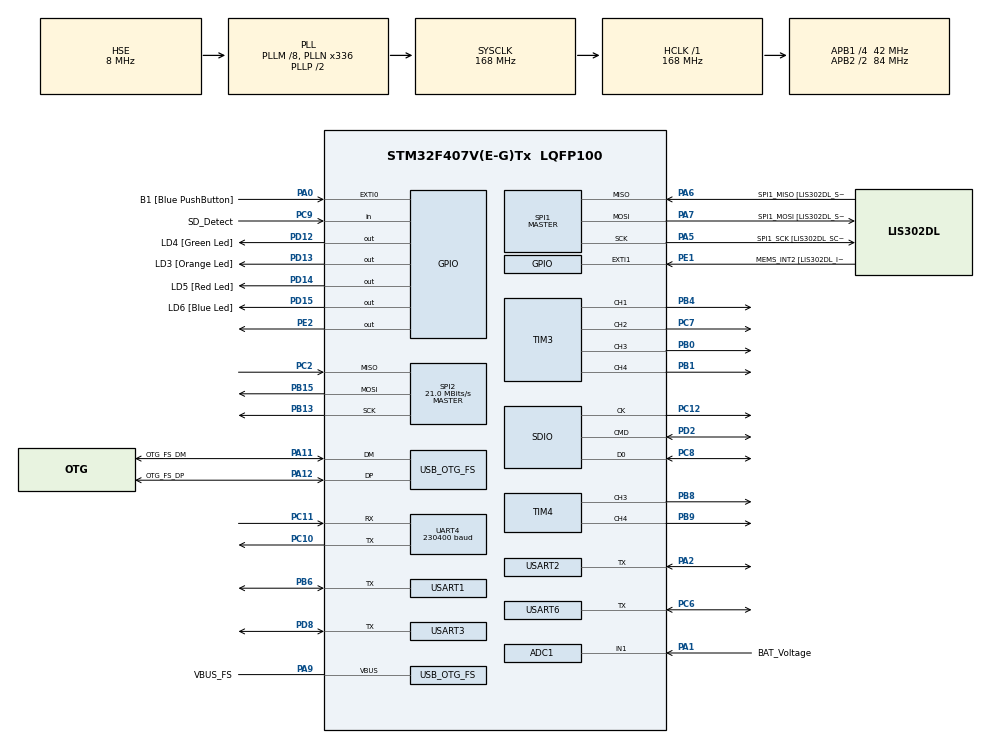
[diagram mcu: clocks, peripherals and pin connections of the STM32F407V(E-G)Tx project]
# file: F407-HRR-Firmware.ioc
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ADC1.Channel-2\#ChannelRegularConversion=ADC_CHANNEL_1
ADC1.EOCSelection=ADC_EOC_SEQ_CONV
ADC1.EnableAnalogWatchDog=false
ADC1.NbrOfConversion=1
ADC1.NbrOfConversionFlag=1
ADC1.Rank-2\#ChannelRegularConversion=1
ADC1.SamplingTime-2\#ChannelRegularConversion=ADC_SAMPLETIME_15CYCLES
ADC1.ScanConvMode=DISABLE
ADC1.master=1
Dma.ADC1.0.Direction=DMA_PERIPH_TO_MEMORY
Dma.ADC1.0.FIFOMode=DMA_FIFOMODE_DISABLE
Dma.ADC1.0.Instance=DMA2_Stream0
Dma.ADC1.0.MemDataAlignment=DMA_MDATAALIGN_WORD
Dma.ADC1.0.MemInc=DMA_MINC_ENABLE
Dma.ADC1.0.Mode=DMA_NORMAL
Dma.ADC1.0.PeriphDataAlignment=DMA_PDATAALIGN_WORD
Dma.ADC1.0.PeriphInc=DMA_PINC_DISABLE
Dma.ADC1.0.Priority=DMA_PRIORITY_LOW
Dma.Request0=ADC1
Dma.Request1=USART1_TX
Dma.Request2=USART2_TX
Dma.Request3=USART3_TX
Dma.Request4=USART6_TX
Dma.USART1_TX.1.Direction=DMA_MEMORY_TO_PERIPH
Dma.USART1_TX.1.FIFOMode=DMA_FIFOMODE_DISABLE
Dma.USART1_TX.1.Instance=DMA2_Stream7
Dma.USART1_TX.1.MemDataAlignment=DMA_MDATAALIGN_BYTE
Dma.USART1_TX.1.MemInc=DMA_MINC_ENABLE
Dma.USART1_TX.1.Mode=DMA_NORMAL
Dma.USART1_TX.1.PeriphDataAlignment=DMA_PDATAALIGN_BYTE
Dma.USART1_TX.1.PeriphInc=DMA_PINC_DISABLE
Dma.USART1_TX.1.Priority=DMA_PRIORITY_LOW
Dma.USART2_TX.2.Direction=DMA_MEMORY_TO_PERIPH
Dma.USART2_TX.2.FIFOMode=DMA_FIFOMODE_DISABLE
Dma.USART2_TX.2.Instance=DMA1_Stream6
Dma.USART2_TX.2.MemDataAlignment=DMA_MDATAALIGN_BYTE
Dma.USART2_TX.2.MemInc=DMA_MINC_ENABLE
Dma.USART2_TX.2.Mode=DMA_NORMAL
Dma.USART2_TX.2.PeriphDataAlignment=DMA_PDATAALIGN_BYTE
Dma.USART2_TX.2.PeriphInc=DMA_PINC_DISABLE
Dma.USART2_TX.2.Priority=DMA_PRIORITY_LOW
Dma.USART3_TX.3.Direction=DMA_MEMORY_TO_PERIPH
Dma.USART3_TX.3.FIFOMode=DMA_FIFOMODE_DISABLE
Dma.USART3_TX.3.Instance=DMA1_Stream3
Dma.USART3_TX.3.MemDataAlignment=DMA_MDATAALIGN_BYTE
Dma.USART3_TX.3.MemInc=DMA_MINC_ENABLE
Dma.USART3_TX.3.Mode=DMA_NORMAL
Dma.USART3_TX.3.PeriphDataAlignment=DMA_PDATAALIGN_BYTE
Dma.USART3_TX.3.PeriphInc=DMA_PINC_DISABLE
Dma.USART3_TX.3.Priority=DMA_PRIORITY_LOW
Dma.USART6_TX.4.Direction=DMA_MEMORY_TO_PERIPH
Dma.USART6_TX.4.FIFOMode=DMA_FIFOMODE_DISABLE
Dma.USART6_TX.4.Instance=DMA2_Stream6
Dma.USART6_TX.4.MemDataAlignment=DMA_MDATAALIGN_BYTE
Dma.USART6_TX.4.MemInc=DMA_MINC_ENABLE
Dma.USART6_TX.4.Mode=DMA_NORMAL
Dma.USART6_TX.4.PeriphDataAlignment=DMA_PDATAALIGN_BYTE
Dma.USART6_TX.4.PeriphInc=DMA_PINC_DISABLE
Dma.USART6_TX.4.Priority=DMA_PRIORITY_LOW
FATFS.BSP.number=1
FATFS._FS_LOCK=16
FATFS0.BSP.STBoard=false
FATFS0.BSP.api=Unknown
FATFS0.BSP.instance=PC9
FATFS0.BSP.ip=GPIO
FATFS0.BSP.mode=Input
FATFS0.BSP.name=Detect_SDIO
FATFS0.BSP.solution=PC9
Mcu.Family=STM32F4
Mcu.Name=STM32F407V(E-G)Tx
Mcu.Package=LQFP100
NVIC.DMA1_Stream3_IRQn=true\:0\:0\:false\:false\:true\:false\:true\:true
NVIC.DMA1_Stream6_IRQn=true\:0\:0\:false\:false\:true\:false\:true\:true
NVIC.DMA2_Stream0_IRQn=true\:0\:0\:false\:false\:true\:false\:true\:true
NVIC.DMA2_Stream6_IRQn=true\:0\:0\:false\:false\:true\:false\:true\:true
NVIC.DMA2_Stream7_IRQn=true\:0\:0\:false\:false\:true\:false\:true\:true
NVIC.OTG_FS_IRQn=true\:0\:0\:false\:false\:true\:true\:true\:true
NVIC.PriorityGroup=NVIC_PRIORITYGROUP_4
NVIC.TIM6_DAC_IRQn=true\:8\:0\:true\:false\:true\:true\:true\:true
NVIC.UART4_IRQn=true\:0\:0\:false\:false\:true\:true\:true\:true
NVIC.USART1_IRQn=true\:0\:0\:false\:false\:true\:true\:true\:true
NVIC.USART2_IRQn=true\:0\:0\:false\:false\:true\:true\:true\:true
NVIC.USART3_IRQn=true\:0\:0\:false\:false\:true\:true\:true\:true
NVIC.USART6_IRQn=true\:0\:0\:false\:false\:true\:true\:true\:true
PA0-WKUP.GPIO_Label=B1 [Blue PushButton]
PA0-WKUP.GPIO_ModeDefaultEXTI=GPIO_MODE_EVT_RISING
PA0-WKUP.GPIO_PuPd=GPIO_NOPULL
PA0-WKUP.Signal=GPXTI0
PA1.GPIO_Label=BAT_Voltage
PA1.Signal=SharedAnalog_PA1
PA10.GPIO_Label=OTG_FS_ID
PA10.GPIO_Mode=GPIO_MODE_AF_PP
PA10.GPIO_PuPd=GPIO_NOPULL
PA10.GPIO_Speed=GPIO_SPEED_FREQ_LOW
PA10.Signal=USB_OTG_FS_ID
PA11.GPIO_Label=OTG_FS_DM
PA11.GPIO_Mode=GPIO_MODE_AF_PP
PA11.GPIO_PuPd=GPIO_NOPULL
PA11.GPIO_Speed=GPIO_SPEED_FREQ_LOW
PA11.Mode=Device_Only
PA11.Signal=USB_OTG_FS_DM
PA12.GPIO_Label=OTG_FS_DP
PA12.GPIO_Mode=GPIO_MODE_AF_PP
PA12.GPIO_PuPd=GPIO_NOPULL
PA12.GPIO_Speed=GPIO_SPEED_FREQ_LOW
PA12.Mode=Device_Only
PA12.Signal=USB_OTG_FS_DP
PA13.GPIO_Label=SWDIO
PA13.Mode=Serial_Wire
PA13.Signal=SYS_JTMS-SWDIO
PA14.GPIO_Label=SWCLK
PA14.Mode=Serial_Wire
PA14.Signal=SYS_JTCK-SWCLK
PA2.GPIO_ModeDefaultOD=GPIO_MODE_AF_PP
PA2.GPIO_PuPd=GPIO_PULLUP
PA2.Mode=Half_duplex(single_wire_mode)
PA2.Signal=USART2_TX
PA5.GPIO_Label=SPI1_SCK [LIS302DL_SCL/SPC]
PA5.GPIO_Mode=GPIO_MODE_AF_PP
PA5.GPIO_PuPd=GPIO_NOPULL
PA5.GPIO_Speed=GPIO_SPEED_FREQ_LOW
PA5.Mode=Full_Duplex_Master
PA5.Signal=SPI1_SCK
PA6.GPIO_Label=SPI1_MISO [LIS302DL_SDO]
PA6.GPIO_Mode=GPIO_MODE_AF_PP
PA6.GPIO_PuPd=GPIO_NOPULL
PA6.GPIO_Speed=GPIO_SPEED_FREQ_LOW
PA6.Mode=Full_Duplex_Master
PA6.Signal=SPI1_MISO
PA7.GPIO_Label=SPI1_MOSI [LIS302DL_SDA/SDI/SDO]
PA7.GPIO_Mode=GPIO_MODE_AF_PP
PA7.GPIO_PuPd=GPIO_NOPULL
PA7.GPIO_Speed=GPIO_SPEED_FREQ_LOW
PA7.Mode=Full_Duplex_Master
PA7.Signal=SPI1_MOSI
PA9.GPIO_Label=VBUS_FS
PA9.GPIO_Mode=GPIO_MODE_INPUT
PA9.GPIO_PuPd=GPIO_NOPULL
PA9.Mode=Activate_VBUS
PA9.Signal=USB_OTG_FS_VBUS
PB0.Signal=S_TIM3_CH3
PB1.Signal=S_TIM3_CH4
PB10.GPIO_Label=CLK_IN [MP45DT02_CLK]
PB10.GPIO_Mode=GPIO_MODE_AF_PP
PB10.GPIO_PuPd=GPIO_NOPULL
PB10.GPIO_Speed=GPIO_SPEED_FREQ_LOW
PB10.Signal=I2S2_CK
PB13.Mode=Full_Duplex_Master
PB13.Signal=SPI2_SCK
PB15.Mode=Full_Duplex_Master
PB15.Signal=SPI2_MOSI
PB3.GPIO_Label=SWO
PB3.Signal=SYS_JTDO-SWO
PB4.Signal=S_TIM3_CH1
PB6.GPIO_ModeDefaultOD=GPIO_MODE_AF_PP
PB6.GPIO_PuPd=GPIO_PULLUP
PB6.Mode=Half_duplex(single_wire_mode)
PB6.Signal=USART1_TX
PB8.Signal=S_TIM4_CH3
PB9.Signal=S_TIM4_CH4
PC10.Mode=Asynchronous
PC10.Signal=UART4_TX
PC11.GPIO_PuPd=GPIO_PULLUP
PC11.Mode=Asynchronous
PC11.Signal=UART4_RX
PC12.Mode=SD_1_bit
PC12.Signal=SDIO_CK
PC14-OSC32_IN.GPIO_Label=PC14-OSC32_IN
PC14-OSC32_IN.Mode=LSE-External-Oscillator
PC14-OSC32_IN.Signal=RCC_OSC32_IN
PC15-OSC32_OUT.GPIO_Label=PC15-OSC32_OUT
PC15-OSC32_OUT.Mode=LSE-External-Oscillator
PC15-OSC32_OUT.Signal=RCC_OSC32_OUT
PC2.Mode=Full_Duplex_Master
PC2.Signal=SPI2_MISO
PC3.GPIO_Label=PDM_OUT [MP45DT02_DOUT]
PC3.GPIO_Mode=GPIO_MODE_AF_PP
PC3.GPIO_PuPd=GPIO_NOPULL
PC3.GPIO_Speed=GPIO_SPEED_FREQ_LOW
PC3.Signal=I2S2_SD
PC6.GPIO_ModeDefaultOD=GPIO_MODE_AF_PP
PC6.GPIO_PuPd=GPIO_PULLUP
PC6.Mode=Half_duplex(single_wire_mode)
PC6.Signal=USART6_TX
PC7.Signal=S_TIM3_CH2
PC8.Mode=SD_1_bit
PC8.Signal=SDIO_D0
PC9.GPIO_Label=SD_Detect
PC9.GPIO_PuPd=GPIO_PULLDOWN
PC9.Signal=GPIO_Input
PD12.GPIO_Label=LD4 [Green Led]
PD12.GPIO_PuPd=GPIO_NOPULL
PD12.GPIO_Speed=GPIO_SPEED_FREQ_LOW
PD12.Signal=GPIO_Output
PD13.GPIO_Label=LD3 [Orange Led]
PD13.Signal=GPIO_Output
PD14.GPIO_Label=LD5 [Red Led]
PD14.GPIO_PuPd=GPIO_NOPULL
PD14.GPIO_Speed=GPIO_SPEED_FREQ_LOW
PD14.Signal=GPIO_Output
PD15.GPIO_Label=LD6 [Blue Led]
PD15.GPIO_PuPd=GPIO_NOPULL
PD15.GPIO_Speed=GPIO_SPEED_FREQ_LOW
PD15.Signal=GPIO_Output
PD2.Mode=SD_1_bit
PD2.Signal=SDIO_CMD
PD8.GPIO_ModeDefaultOD=GPIO_MODE_AF_PP
PD8.GPIO_PuPd=GPIO_PULLUP
PD8.Mode=Half_duplex(single_wire_mode)
PD8.Signal=USART3_TX
PE1.GPIO_Label=MEMS_INT2 [LIS302DL_INT2]
PE1.GPIO_ModeDefaultEXTI=GPIO_MODE_EVT_RISING
PE1.GPIO_PuPd=GPIO_NOPULL
PE1.Signal=GPXTI1
PE2.Signal=GPIO_Output
PH0-OSC_IN.GPIO_Label=PH0-OSC_IN
PH0-OSC_IN.Mode=HSE-External-Oscillator
PH0-OSC_IN.Signal=RCC_OSC_IN
PH1-OSC_OUT.GPIO_Label=PH1-OSC_OUT
PH1-OSC_OUT.Mode=HSE-External-Oscillator
PH1-OSC_OUT.Signal=RCC_OSC_OUT
ProjectManager.HeapSize=0x200
ProjectManager.StackSize=0x400
ProjectManager.TargetToolchain=STM32CubeIDE
RCC.48MHZClocksFreq_Value=48000000
RCC.AHBFreq_Value=168000000
RCC.APB1CLKDivider=RCC_HCLK_DIV4
RCC.APB1Freq_Value=42000000
RCC.APB1TimFreq_Value=84000000
RCC.APB2CLKDivider=RCC_HCLK_DIV2
RCC.APB2Freq_Value=84000000
RCC.APB2TimFreq_Value=168000000
RCC.CortexFreq_Value=168000000
RCC.HCLKFreq_Value=168000000
RCC.HSE_VALUE=8000000
RCC.HSI_VALUE=16000000
RCC.PLLM=8
RCC.PLLN=336
RCC.PLLQ=7
RCC.SYSCLKFreq_VALUE=168000000
RCC.SYSCLKSource=RCC_SYSCLKSOURCE_PLLCLK
RCC.VCOOutputFreq_Value=336000000
SH.S_TIM3_CH1.0=TIM3_CH1,PWM Generation1 CH1
SH.S_TIM3_CH2.0=TIM3_CH2,PWM Generation2 CH2
SH.S_TIM3_CH3.0=TIM3_CH3,PWM Generation3 CH3
SH.S_TIM3_CH4.0=TIM3_CH4,PWM Generation4 CH4
SH.S_TIM4_CH3.0=TIM4_CH3,PWM Generation3 CH3
SH.S_TIM4_CH4.0=TIM4_CH4,PWM Generation4 CH4
SH.SharedAnalog_PA1.0=GPIO_Analog
SH.SharedAnalog_PA1.1=ADC1_IN1,IN1
SPI1.BaudRatePrescaler-Full_Duplex_Master=SPI_BAUDRATEPRESCALER_2
SPI1.CalculateBaudRate-Full_Duplex_Master=42.0 MBits/s
SPI1.Direction=SPI_DIRECTION_2LINES
SPI1.Mode=SPI_MODE_MASTER
SPI1.Mode-Full_Duplex_Master=SPI_MODE_MASTER
SPI1.VirtualType=VM_MASTER
SPI2.CalculateBaudRate=21.0 MBits/s
SPI2.Direction=SPI_DIRECTION_2LINES
SPI2.Mode=SPI_MODE_MASTER
SPI2.VirtualType=VM_MASTER
TIM3.Channel-PWM\ Generation1\ CH1=TIM_CHANNEL_1
TIM3.Channel-PWM\ Generation2\ CH2=TIM_CHANNEL_2
TIM3.Channel-PWM\ Generation3\ CH3=TIM_CHANNEL_3
TIM3.Channel-PWM\ Generation4\ CH4=TIM_CHANNEL_4
TIM4.Channel-PWM\ Generation3\ CH3=TIM_CHANNEL_3
TIM4.Channel-PWM\ Generation4\ CH4=TIM_CHANNEL_4
TIM6.Period=99
TIM6.Prescaler=8399
UART4.BaudRate=230400
UART4.VirtualMode=Asynchronous
USART1.BaudRate=1000000
USART1.VirtualMode=VM_ASYNC
USART2.BaudRate=1000000
USART2.VirtualMode=VM_ASYNC
USART3.BaudRate=1000000
USART3.VirtualMode=VM_ASYNC
USART6.BaudRate=1000000
USART6.VirtualMode=VM_ASYNC
USB_DEVICE.CLASS_NAME_FS=CDC
USB_DEVICE.VirtualMode-CDC_FS=Cdc
USB_DEVICE.VirtualModeFS=Cdc_FS
USB_OTG_FS.VirtualMode=Device_Only
VP_ADC1_TempSens_Input.Mode=IN-TempSens
VP_ADC1_Vref_Input.Mode=IN-Vrefint
VP_FATFS_VS_SDIO.Mode=SDIO
VP_TIM6_VS_ClockSourceINT.Mode=Enable_Timer
VP_USB_DEVICE_VS_USB_DEVICE_CDC_FS.Mode=CDC_FS
board=STM32F407G-DISC1

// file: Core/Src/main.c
/* USER CODE BEGIN Header */
/**
  ******************************************************************************
  * @file           : main.c
  * @brief          : Main program body
  ******************************************************************************
  * @attention
  *
  * Copyright (c) 2022 STMicroelectronics.
  * All rights reserved.
  *
  * This software is licensed under terms that can be found in the LICENSE file
  * in the root directory of this software component.
  * If no LICENSE file comes with this software, it is provided AS-IS.
  *
  ******************************************************************************
  */
/* USER CODE END Header */
#include "main.h"
#include "fatfs.h"
#include "usb_device.h"

/* USER CODE BEGIN Includes */
#include "Components\Start.hpp"
/* USER CODE END Includes */

 ADC_HandleTypeDef hadc1;
DMA_HandleTypeDef hdma_adc1;

SD_HandleTypeDef hsd;

SPI_HandleTypeDef hspi1;
SPI_HandleTypeDef hspi2;

TIM_HandleTypeDef htim3;
TIM_HandleTypeDef htim4;
TIM_HandleTypeDef htim6;

UART_HandleTypeDef huart4;
UART_HandleTypeDef huart1;
UART_HandleTypeDef huart2;
UART_HandleTypeDef huart3;
UART_HandleTypeDef huart6;
DMA_HandleTypeDef hdma_usart1_tx;
DMA_HandleTypeDef hdma_usart2_tx;
DMA_HandleTypeDef hdma_usart3_tx;
DMA_HandleTypeDef hdma_usart6_tx;

void SystemClock_Config(void);
static void MX_GPIO_Init(void);
static void MX_SPI1_Init(void);
static void MX_SDIO_SD_Init(void);
static void MX_DMA_Init(void);
static void MX_SPI2_Init(void);
static void MX_TIM3_Init(void);
static void MX_TIM4_Init(void);
static void MX_TIM6_Init(void);
static void MX_USART1_UART_Init(void);
static void MX_USART2_UART_Init(void);
static void MX_USART3_UART_Init(void);
static void MX_USART6_UART_Init(void);
static void MX_ADC1_Init(void);
static void MX_UART4_Init(void);

int main(void)
{

  /* MCU Configuration--------------------------------------------------------*/

  /* Reset of all peripherals, Initializes the Flash interface and the Systick. */
  HAL_Init();

  /* Configure the system clock */
  SystemClock_Config();

  /* Initialize all configured peripherals */
  MX_GPIO_Init();
  MX_SPI1_Init();
  MX_USB_DEVICE_Init();
  MX_SDIO_SD_Init();
  MX_FATFS_Init();
  MX_DMA_Init();
  MX_SPI2_Init();
  MX_TIM3_Init();
  MX_TIM4_Init();
  MX_TIM6_Init();
  MX_USART1_UART_Init();
  MX_USART2_UART_Init();
  MX_USART3_UART_Init();
  MX_USART6_UART_Init();
  MX_ADC1_Init();
  MX_UART4_Init();
  /* USER CODE BEGIN 2 */
  HAL_TIM_Base_Start_IT(&htim6);
  Start();
  /* USER CODE END 2 */

  /* Infinite loop */
  /* USER CODE BEGIN WHILE */
  //Não deve chegar aqui
  while (1)
  {
    /* USER CODE END WHILE */

  }
}

void SystemClock_Config(void)
{
  RCC_OscInitTypeDef RCC_OscInitStruct = {0};
  RCC_ClkInitTypeDef RCC_ClkInitStruct = {0};

  /** Configure the main internal regulator output voltage
  */
  __HAL_RCC_PWR_CLK_ENABLE();
  __HAL_PWR_VOLTAGESCALING_CONFIG(PWR_REGULATOR_VOLTAGE_SCALE1);

  /** Initializes the RCC Oscillators according to the specified parameters
  * in the RCC_OscInitTypeDef structure.
  */
  RCC_OscInitStruct.OscillatorType = RCC_OSCILLATORTYPE_HSE;
  RCC_OscInitStruct.HSEState = RCC_HSE_ON;
  RCC_OscInitStruct.PLL.PLLState = RCC_PLL_ON;
  RCC_OscInitStruct.PLL.PLLSource = RCC_PLLSOURCE_HSE;
  RCC_OscInitStruct.PLL.PLLM = 8;
  RCC_OscInitStruct.PLL.PLLN = 336;
  RCC_OscInitStruct.PLL.PLLP = RCC_PLLP_DIV2;
  RCC_OscInitStruct.PLL.PLLQ = 7;
  if (HAL_RCC_OscConfig(&RCC_OscInitStruct) != HAL_OK)
  {
    Error_Handler();
  }

  /** Initializes the CPU, AHB and APB buses clocks
  */
  RCC_ClkInitStruct.ClockType = RCC_CLOCKTYPE_HCLK|RCC_CLOCKTYPE_SYSCLK
                              |RCC_CLOCKTYPE_PCLK1|RCC_CLOCKTYPE_PCLK2;
  RCC_ClkInitStruct.SYSCLKSource = RCC_SYSCLKSOURCE_PLLCLK;
  RCC_ClkInitStruct.AHBCLKDivider = RCC_SYSCLK_DIV1;
  RCC_ClkInitStruct.APB1CLKDivider = RCC_HCLK_DIV4;
  RCC_ClkInitStruct.APB2CLKDivider = RCC_HCLK_DIV2;

  if (HAL_RCC_ClockConfig(&RCC_ClkInitStruct, FLASH_LATENCY_5) != HAL_OK)
  {
    Error_Handler();
  }
}

static void MX_ADC1_Init(void)
{

  ADC_ChannelConfTypeDef sConfig = {0};

  /** Configure the global features of the ADC (Clock, Resolution, Data Alignment and number of conversion)
  */
  hadc1.Instance = ADC1;
  hadc1.Init.ClockPrescaler = ADC_CLOCK_SYNC_PCLK_DIV4;
  hadc1.Init.Resolution = ADC_RESOLUTION_12B;
  hadc1.Init.ScanConvMode = DISABLE;
  hadc1.Init.ContinuousConvMode = DISABLE;
  hadc1.Init.DiscontinuousConvMode = DISABLE;
  hadc1.Init.ExternalTrigConvEdge = ADC_EXTERNALTRIGCONVEDGE_NONE;
  hadc1.Init.ExternalTrigConv = ADC_SOFTWARE_START;
  hadc1.Init.DataAlign = ADC_DATAALIGN_RIGHT;
  hadc1.Init.NbrOfConversion = 1;
  hadc1.Init.DMAContinuousRequests = DISABLE;
  hadc1.Init.EOCSelection = ADC_EOC_SEQ_CONV;
  if (HAL_ADC_Init(&hadc1) != HAL_OK)
  {
    Error_Handler();
  }

  /** Configure for the selected ADC regular channel its corresponding rank in the sequencer and its sample time.
  */
  sConfig.Channel = ADC_CHANNEL_1;
  sConfig.Rank = 1;
  sConfig.SamplingTime = ADC_SAMPLETIME_15CYCLES;
  if (HAL_ADC_ConfigChannel(&hadc1, &sConfig) != HAL_OK)
  {
    Error_Handler();
  }

}

static void MX_SDIO_SD_Init(void)
{

  hsd.Instance = SDIO;
  hsd.Init.ClockEdge = SDIO_CLOCK_EDGE_RISING;
  hsd.Init.ClockBypass = SDIO_CLOCK_BYPASS_DISABLE;
  hsd.Init.ClockPowerSave = SDIO_CLOCK_POWER_SAVE_DISABLE;
  hsd.Init.BusWide = SDIO_BUS_WIDE_1B;
  hsd.Init.HardwareFlowControl = SDIO_HARDWARE_FLOW_CONTROL_DISABLE;
  hsd.Init.ClockDiv = 0;

}

static void MX_SPI1_Init(void)
{

  /* SPI1 parameter configuration*/
  hspi1.Instance = SPI1;
  hspi1.Init.Mode = SPI_MODE_MASTER;
  hspi1.Init.Direction = SPI_DIRECTION_2LINES;
  hspi1.Init.DataSize = SPI_DATASIZE_8BIT;
  hspi1.Init.CLKPolarity = SPI_POLARITY_LOW;
  hspi1.Init.CLKPhase = SPI_PHASE_1EDGE;
  hspi1.Init.NSS = SPI_NSS_SOFT;
  hspi1.Init.BaudRatePrescaler = SPI_BAUDRATEPRESCALER_2;
  hspi1.Init.FirstBit = SPI_FIRSTBIT_MSB;
  hspi1.Init.TIMode = SPI_TIMODE_DISABLE;
  hspi1.Init.CRCCalculation = SPI_CRCCALCULATION_DISABLE;
  hspi1.Init.CRCPolynomial = 10;
  if (HAL_SPI_Init(&hspi1) != HAL_OK)
  {
    Error_Handler();
  }

}

static void MX_SPI2_Init(void)
{

  /* SPI2 parameter configuration*/
  hspi2.Instance = SPI2;
  hspi2.Init.Mode = SPI_MODE_MASTER;
  hspi2.Init.Direction = SPI_DIRECTION_2LINES;
  hspi2.Init.DataSize = SPI_DATASIZE_8BIT;
  hspi2.Init.CLKPolarity = SPI_POLARITY_LOW;
  hspi2.Init.CLKPhase = SPI_PHASE_1EDGE;
  hspi2.Init.NSS = SPI_NSS_SOFT;
  hspi2.Init.BaudRatePrescaler = SPI_BAUDRATEPRESCALER_2;
  hspi2.Init.FirstBit = SPI_FIRSTBIT_MSB;
  hspi2.Init.TIMode = SPI_TIMODE_DISABLE;
  hspi2.Init.CRCCalculation = SPI_CRCCALCULATION_DISABLE;
  hspi2.Init.CRCPolynomial = 10;
  if (HAL_SPI_Init(&hspi2) != HAL_OK)
  {
    Error_Handler();
  }

}

static void MX_TIM3_Init(void)
{

  TIM_MasterConfigTypeDef sMasterConfig = {0};
  TIM_OC_InitTypeDef sConfigOC = {0};

  htim3.Instance = TIM3;
  htim3.Init.Prescaler = 0;
  htim3.Init.CounterMode = TIM_COUNTERMODE_UP;
  htim3.Init.Period = 65535;
  htim3.Init.ClockDivision = TIM_CLOCKDIVISION_DIV1;
  htim3.Init.AutoReloadPreload = TIM_AUTORELOAD_PRELOAD_DISABLE;
  if (HAL_TIM_PWM_Init(&htim3) != HAL_OK)
  {
    Error_Handler();
  }
  sMasterConfig.MasterOutputTrigger = TIM_TRGO_RESET;
  sMasterConfig.MasterSlaveMode = TIM_MASTERSLAVEMODE_DISABLE;
  if (HAL_TIMEx_MasterConfigSynchronization(&htim3, &sMasterConfig) != HAL_OK)
  {
    Error_Handler();
  }
  sConfigOC.OCMode = TIM_OCMODE_PWM1;
  sConfigOC.Pulse = 0;
  sConfigOC.OCPolarity = TIM_OCPOLARITY_HIGH;
  sConfigOC.OCFastMode = TIM_OCFAST_DISABLE;
  if (HAL_TIM_PWM_ConfigChannel(&htim3, &sConfigOC, TIM_CHANNEL_1) != HAL_OK)
  {
    Error_Handler();
  }
  if (HAL_TIM_PWM_ConfigChannel(&htim3, &sConfigOC, TIM_CHANNEL_2) != HAL_OK)
  {
    Error_Handler();
  }
  if (HAL_TIM_PWM_ConfigChannel(&htim3, &sConfigOC, TIM_CHANNEL_3) != HAL_OK)
  {
    Error_Handler();
  }
  if (HAL_TIM_PWM_ConfigChannel(&htim3, &sConfigOC, TIM_CHANNEL_4) != HAL_OK)
  {
    Error_Handler();
  }
  HAL_TIM_MspPostInit(&htim3);

}

static void MX_TIM4_Init(void)
{

  TIM_MasterConfigTypeDef sMasterConfig = {0};
  TIM_OC_InitTypeDef sConfigOC = {0};

  htim4.Instance = TIM4;
  htim4.Init.Prescaler = 0;
  htim4.Init.CounterMode = TIM_COUNTERMODE_UP;
  htim4.Init.Period = 65535;
  htim4.Init.ClockDivision = TIM_CLOCKDIVISION_DIV1;
  htim4.Init.AutoReloadPreload = TIM_AUTORELOAD_PRELOAD_DISABLE;
  if (HAL_TIM_PWM_Init(&htim4) != HAL_OK)
  {
    Error_Handler();
  }
  sMasterConfig.MasterOutputTrigger = TIM_TRGO_RESET;
  sMasterConfig.MasterSlaveMode = TIM_MASTERSLAVEMODE_DISABLE;
  if (HAL_TIMEx_MasterConfigSynchronization(&htim4, &sMasterConfig) != HAL_OK)
  {
    Error_Handler();
  }
  sConfigOC.OCMode = TIM_OCMODE_PWM1;
  sConfigOC.Pulse = 0;
  sConfigOC.OCPolarity = TIM_OCPOLARITY_HIGH;
  sConfigOC.OCFastMode = TIM_OCFAST_DISABLE;
  if (HAL_TIM_PWM_ConfigChannel(&htim4, &sConfigOC, TIM_CHANNEL_3) != HAL_OK)
  {
    Error_Handler();
  }
  if (HAL_TIM_PWM_ConfigChannel(&htim4, &sConfigOC, TIM_CHANNEL_4) != HAL_OK)
  {
    Error_Handler();
  }
  HAL_TIM_MspPostInit(&htim4);

}

static void MX_TIM6_Init(void)
{

  TIM_MasterConfigTypeDef sMasterConfig = {0};

  htim6.Instance = TIM6;
  htim6.Init.Prescaler = 8399;
  htim6.Init.CounterMode = TIM_COUNTERMODE_UP;
  htim6.Init.Period = 99;
  htim6.Init.AutoReloadPreload = TIM_AUTORELOAD_PRELOAD_DISABLE;
  if (HAL_TIM_Base_Init(&htim6) != HAL_OK)
  {
    Error_Handler();
  }
  sMasterConfig.MasterOutputTrigger = TIM_TRGO_RESET;
  sMasterConfig.MasterSlaveMode = TIM_MASTERSLAVEMODE_DISABLE;
  if (HAL_TIMEx_MasterConfigSynchronization(&htim6, &sMasterConfig) != HAL_OK)
  {
    Error_Handler();
  }

}

static void MX_UART4_Init(void)
{

  huart4.Instance = UART4;
  huart4.Init.BaudRate = 230400;
  huart4.Init.WordLength = UART_WORDLENGTH_8B;
  huart4.Init.StopBits = UART_STOPBITS_1;
  huart4.Init.Parity = UART_PARITY_NONE;
  huart4.Init.Mode = UART_MODE_TX_RX;
  huart4.Init.HwFlowCtl = UART_HWCONTROL_NONE;
  huart4.Init.OverSampling = UART_OVERSAMPLING_16;
  if (HAL_UART_Init(&huart4) != HAL_OK)
  {
    Error_Handler();
  }

}

static void MX_USART1_UART_Init(void)
{

  huart1.Instance = USART1;
  huart1.Init.BaudRate = 1000000;
  huart1.Init.WordLength = UART_WORDLENGTH_8B;
  huart1.Init.StopBits = UART_STOPBITS_1;
  huart1.Init.Parity = UART_PARITY_NONE;
  huart1.Init.Mode = UART_MODE_TX_RX;
  huart1.Init.HwFlowCtl = UART_HWCONTROL_NONE;
  huart1.Init.OverSampling = UART_OVERSAMPLING_16;
  if (HAL_HalfDuplex_Init(&huart1) != HAL_OK)
  {
    Error_Handler();
  }

}

static void MX_USART2_UART_Init(void)
{

  huart2.Instance = USART2;
  huart2.Init.BaudRate = 1000000;
  huart2.Init.WordLength = UART_WORDLENGTH_8B;
  huart2.Init.StopBits = UART_STOPBITS_1;
  huart2.Init.Parity = UART_PARITY_NONE;
  huart2.Init.Mode = UART_MODE_TX_RX;
  huart2.Init.HwFlowCtl = UART_HWCONTROL_NONE;
  huart2.Init.OverSampling = UART_OVERSAMPLING_16;
  if (HAL_HalfDuplex_Init(&huart2) != HAL_OK)
  {
    Error_Handler();
  }

}

static void MX_USART3_UART_Init(void)
{

  huart3.Instance = USART3;
  huart3.Init.BaudRate = 1000000;
  huart3.Init.WordLength = UART_WORDLENGTH_8B;
  huart3.Init.StopBits = UART_STOPBITS_1;
  huart3.Init.Parity = UART_PARITY_NONE;
  huart3.Init.Mode = UART_MODE_TX_RX;
  huart3.Init.HwFlowCtl = UART_HWCONTROL_NONE;
  huart3.Init.OverSampling = UART_OVERSAMPLING_16;
  if (HAL_HalfDuplex_Init(&huart3) != HAL_OK)
  {
    Error_Handler();
  }

}

static void MX_USART6_UART_Init(void)
{

  huart6.Instance = USART6;
  huart6.Init.BaudRate = 1000000;
  huart6.Init.WordLength = UART_WORDLENGTH_8B;
  huart6.Init.StopBits = UART_STOPBITS_1;
  huart6.Init.Parity = UART_PARITY_NONE;
  huart6.Init.Mode = UART_MODE_TX_RX;
  huart6.Init.HwFlowCtl = UART_HWCONTROL_NONE;
  huart6.Init.OverSampling = UART_OVERSAMPLING_16;
  if (HAL_HalfDuplex_Init(&huart6) != HAL_OK)
  {
    Error_Handler();
  }

}

static void MX_DMA_Init(void)
{

  /* DMA controller clock enable */
  __HAL_RCC_DMA2_CLK_ENABLE();
  __HAL_RCC_DMA1_CLK_ENABLE();

  /* DMA interrupt init */
  /* DMA1_Stream3_IRQn interrupt configuration */
  HAL_NVIC_SetPriority(DMA1_Stream3_IRQn, 0, 0);
  HAL_NVIC_EnableIRQ(DMA1_Stream3_IRQn);
  /* DMA1_Stream6_IRQn interrupt configuration */
  HAL_NVIC_SetPriority(DMA1_Stream6_IRQn, 0, 0);
  HAL_NVIC_EnableIRQ(DMA1_Stream6_IRQn);
  /* DMA2_Stream0_IRQn interrupt configuration */
  HAL_NVIC_SetPriority(DMA2_Stream0_IRQn, 0, 0);
  HAL_NVIC_EnableIRQ(DMA2_Stream0_IRQn);
  /* DMA2_Stream6_IRQn interrupt configuration */
  HAL_NVIC_SetPriority(DMA2_Stream6_IRQn, 0, 0);
  HAL_NVIC_EnableIRQ(DMA2_Stream6_IRQn);
  /* DMA2_Stream7_IRQn interrupt configuration */
  HAL_NVIC_SetPriority(DMA2_Stream7_IRQn, 0, 0);
  HAL_NVIC_EnableIRQ(DMA2_Stream7_IRQn);

}

static void MX_GPIO_Init(void)
{
  GPIO_InitTypeDef GPIO_InitStruct = {0};

  /* GPIO Ports Clock Enable */
  __HAL_RCC_GPIOE_CLK_ENABLE();
  __HAL_RCC_GPIOC_CLK_ENABLE();
  __HAL_RCC_GPIOH_CLK_ENABLE();
  __HAL_RCC_GPIOA_CLK_ENABLE();
  __HAL_RCC_GPIOB_CLK_ENABLE();
  __HAL_RCC_GPIOD_CLK_ENABLE();

  /*Configure GPIO pin Output Level */
  HAL_GPIO_WritePin(GPIOE, GPIO_PIN_2, GPIO_PIN_RESET);

  /*Configure GPIO pin Output Level */
  HAL_GPIO_WritePin(GPIOD, LD4_Pin|LD3_Pin|LD5_Pin|LD6_Pin, GPIO_PIN_RESET);

  /*Configure GPIO pin : PE2 */
  GPIO_InitStruct.Pin = GPIO_PIN_2;
  GPIO_InitStruct.Mode = GPIO_MODE_OUTPUT_PP;
  GPIO_InitStruct.Pull = GPIO_NOPULL;
  GPIO_InitStruct.Speed = GPIO_SPEED_FREQ_LOW;
  HAL_GPIO_Init(GPIOE, &GPIO_InitStruct);

  /*Configure GPIO pin : PDM_OUT_Pin */
  GPIO_InitStruct.Pin = PDM_OUT_Pin;
  GPIO_InitStruct.Mode = GPIO_MODE_AF_PP;
  GPIO_InitStruct.Pull = GPIO_NOPULL;
  GPIO_InitStruct.Speed = GPIO_SPEED_FREQ_LOW;
  GPIO_InitStruct.Alternate = GPIO_AF5_SPI2;
  HAL_GPIO_Init(PDM_OUT_GPIO_Port, &GPIO_InitStruct);

  /*Configure GPIO pin : B1_Pin */
  GPIO_InitStruct.Pin = B1_Pin;
  GPIO_InitStruct.Mode = GPIO_MODE_EVT_RISING;
  GPIO_InitStruct.Pull = GPIO_NOPULL;
  HAL_GPIO_Init(B1_GPIO_Port, &GPIO_InitStruct);

  /*Configure GPIO pin : CLK_IN_Pin */
  GPIO_InitStruct.Pin = CLK_IN_Pin;
  GPIO_InitStruct.Mode = GPIO_MODE_AF_PP;
  GPIO_InitStruct.Pull = GPIO_NOPULL;
  GPIO_InitStruct.Speed = GPIO_SPEED_FREQ_LOW;
  GPIO_InitStruct.Alternate = GPIO_AF5_SPI2;
  HAL_GPIO_Init(CLK_IN_GPIO_Port, &GPIO_InitStruct);

  /*Configure GPIO pins : LD4_Pin LD3_Pin LD5_Pin LD6_Pin */
  GPIO_InitStruct.Pin = LD4_Pin|LD3_Pin|LD5_Pin|LD6_Pin;
  GPIO_InitStruct.Mode = GPIO_MODE_OUTPUT_PP;
  GPIO_InitStruct.Pull = GPIO_NOPULL;
  GPIO_InitStruct.Speed = GPIO_SPEED_FREQ_LOW;
  HAL_GPIO_Init(GPIOD, &GPIO_InitStruct);

  /*Configure GPIO pin : SD_Detect_Pin */
  GPIO_InitStruct.Pin = SD_Detect_Pin;
  GPIO_InitStruct.Mode = GPIO_MODE_INPUT;
  GPIO_InitStruct.Pull = GPIO_PULLDOWN;
  HAL_GPIO_Init(SD_Detect_GPIO_Port, &GPIO_InitStruct);

  /*Configure GPIO pin : MEMS_INT2_Pin */
  GPIO_InitStruct.Pin = MEMS_INT2_Pin;
  GPIO_InitStruct.Mode = GPIO_MODE_EVT_RISING;
  GPIO_InitStruct.Pull = GPIO_NOPULL;
  HAL_GPIO_Init(MEMS_INT2_GPIO_Port, &GPIO_InitStruct);

}

void Error_Handler(void)
{
  /* USER CODE BEGIN Error_Handler_Debug */
  /* User can add his own implementation to report the HAL error return state */
  __disable_irq();
  while (1)
  {
	  HAL_GPIO_TogglePin(LD5_GPIO_Port, LD5_Pin);
	  HAL_Delay(250);
  }
  /* USER CODE END Error_Handler_Debug */
}
